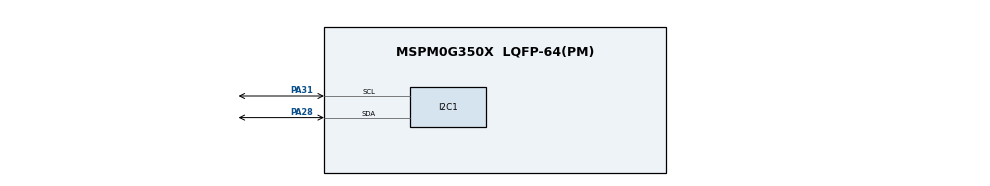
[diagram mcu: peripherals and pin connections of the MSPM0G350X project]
/**
 * @cliArgs --device "MSPM0G350X" --part "Default" --package "LQFP-64(PM)" --product "mspm0_sdk@2.04.00.06"
 * @versions {"tool":"1.22.0+3893"}
 */

/**
 * Import the modules used in this configuration.
 */
const GPIO    = scripting.addModule("/ti/driverlib/GPIO", {}, false);
const GPIO1   = GPIO.addInstance();
const GPIO2   = GPIO.addInstance();
const GPIO3   = GPIO.addInstance();
const GPIO4   = GPIO.addInstance();
const I2C     = scripting.addModule("/ti/driverlib/I2C", {}, false);
const I2C1    = I2C.addInstance();
const SYSCTL  = scripting.addModule("/ti/driverlib/SYSCTL");
const SYSTICK = scripting.addModule("/ti/driverlib/SYSTICK");
const UART    = scripting.addModule("/ti/driverlib/UART", {}, false);
const UART1   = UART.addInstance();

/**
 * Write custom configuration values to the imported modules.
 */
GPIO1.$name                          = "GPIO_OLED";
GPIO1.associatedPins.create(2);
GPIO1.associatedPins[0].$name        = "PIN_SCL";
GPIO1.associatedPins[0].assignedPort = "PORTA";
GPIO1.associatedPins[0].assignedPin  = "25";
GPIO1.associatedPins[1].$name        = "PIN_SDA";
GPIO1.associatedPins[1].assignedPort = "PORTA";
GPIO1.associatedPins[1].assignedPin  = "27";

const Board = scripting.addModule("/ti/driverlib/Board", {}, false);

GPIO2.$name                         = "GPIO_MPU6050";
GPIO2.associatedPins[0].$name       = "PIN_INT";
GPIO2.associatedPins[0].direction   = "INPUT";
GPIO2.associatedPins[0].interruptEn = true;
GPIO2.associatedPins[0].polarity    = "FALL";

GPIO3.$name                          = "Control";
GPIO3.associatedPins.create(4);
GPIO3.associatedPins[0].$name        = "AIN1";
GPIO3.associatedPins[0].initialValue = "SET";
GPIO3.associatedPins[0].assignedPort = "PORTA";
GPIO3.associatedPins[0].assignedPin  = "8";
GPIO3.associatedPins[1].$name        = "AIN2";
GPIO3.associatedPins[1].initialValue = "SET";
GPIO3.associatedPins[1].assignedPort = "PORTA";
GPIO3.associatedPins[1].assignedPin  = "7";
GPIO3.associatedPins[2].$name        = "BIN1";
GPIO3.associatedPins[3].$name        = "BIN2";

GPIO4.$name                              = "encoder";
GPIO4.associatedPins.create(4);
GPIO4.associatedPins[0].$name            = "left_A";
GPIO4.associatedPins[0].direction        = "INPUT";
GPIO4.associatedPins[0].internalResistor = "PULL_UP";
GPIO4.associatedPins[0].interruptEn      = true;
GPIO4.associatedPins[0].assignedPort     = "PORTB";
GPIO4.associatedPins[0].assignedPin      = "4";
GPIO4.associatedPins[0].polarity         = "RISE_FALL";
GPIO4.associatedPins[1].$name            = "left_B";
GPIO4.associatedPins[1].direction        = "INPUT";
GPIO4.associatedPins[1].internalResistor = "PULL_UP";
GPIO4.associatedPins[1].assignedPort     = "PORTB";
GPIO4.associatedPins[1].assignedPin      = "5";
GPIO4.associatedPins[1].interruptEn      = true;
GPIO4.associatedPins[1].polarity         = "RISE_FALL";
GPIO4.associatedPins[2].$name            = "right_A";
GPIO4.associatedPins[2].internalResistor = "PULL_UP";
GPIO4.associatedPins[2].direction        = "INPUT";
GPIO4.associatedPins[2].assignedPort     = "PORTA";
GPIO4.associatedPins[2].assignedPin      = "10";
GPIO4.associatedPins[2].interruptEn      = true;
GPIO4.associatedPins[2].polarity         = "RISE_FALL";
GPIO4.associatedPins[3].$name            = "right_B";
GPIO4.associatedPins[3].direction        = "INPUT";
GPIO4.associatedPins[3].internalResistor = "PULL_UP";
GPIO4.associatedPins[3].assignedPort     = "PORTA";
GPIO4.associatedPins[3].assignedPin      = "11";
GPIO4.associatedPins[3].polarity         = "RISE_FALL";
GPIO4.associatedPins[3].interruptEn      = true;

I2C1.$name                             = "I2C_MPU6050";
I2C1.basicEnableController             = true;
I2C1.basicControllerStandardBusSpeed   = "Fast";
I2C1.peripheral.$assign                = "I2C0";
I2C1.peripheral.sdaPin.$assign         = "PA28";
I2C1.peripheral.sclPin.$assign         = "PA31";
I2C1.sdaPinConfig.hideOutputInversion  = scripting.forceWrite(false);
I2C1.sdaPinConfig.onlyInternalResistor = scripting.forceWrite(false);
I2C1.sdaPinConfig.passedPeripheralType = scripting.forceWrite("Digital");
I2C1.sdaPinConfig.$name                = "ti_driverlib_gpio_GPIOPinGeneric2";
I2C1.sclPinConfig.hideOutputInversion  = scripting.forceWrite(false);
I2C1.sclPinConfig.onlyInternalResistor = scripting.forceWrite(false);
I2C1.sclPinConfig.passedPeripheralType = scripting.forceWrite("Digital");
I2C1.sclPinConfig.$name                = "ti_driverlib_gpio_GPIOPinGeneric3";

SYSCTL.forceDefaultClkConfig = true;
SYSCTL.clockTreeEn           = true;

SYSTICK.periodEnable    = true;
SYSTICK.interruptEnable = true;
SYSTICK.systickEnable   = true;
SYSTICK.period          = 32000;

UART1.$name             = "UART_0";
UART1.txPinConfig.$name = "ti_driverlib_gpio_GPIOPinGeneric0";
UART1.rxPinConfig.$name = "ti_driverlib_gpio_GPIOPinGeneric1";

/**
 * Pinmux solution for unlocked pins/peripherals. This ensures that minor changes to the automatic solver in a future
 * version of the tool will not impact the pinmux you originally saw.  These lines can be completely deleted in order to
 * re-solve from scratch.
 */
GPIO1.associatedPins[0].pin.$suggestSolution = "PA25";
GPIO1.associatedPins[1].pin.$suggestSolution = "PA27";
Board.peripheral.$suggestSolution            = "DEBUGSS";
Board.peripheral.swclkPin.$suggestSolution   = "PA20";
Board.peripheral.swdioPin.$suggestSolution   = "PA19";
GPIO2.associatedPins[0].pin.$suggestSolution = "PB13";
GPIO3.associatedPins[0].pin.$suggestSolution = "PA8";
GPIO3.associatedPins[1].pin.$suggestSolution = "PA7";
GPIO3.associatedPins[2].pin.$suggestSolution = "PB14";
GPIO3.associatedPins[3].pin.$suggestSolution = "PB15";
GPIO4.associatedPins[0].pin.$suggestSolution = "PB4";
GPIO4.associatedPins[1].pin.$suggestSolution = "PB5";
GPIO4.associatedPins[2].pin.$suggestSolution = "PA10";
GPIO4.associatedPins[3].pin.$suggestSolution = "PA11";
UART1.peripheral.$suggestSolution            = "UART0";
UART1.peripheral.rxPin.$suggestSolution      = "PA1";
UART1.peripheral.txPin.$suggestSolution      = "PA0";
